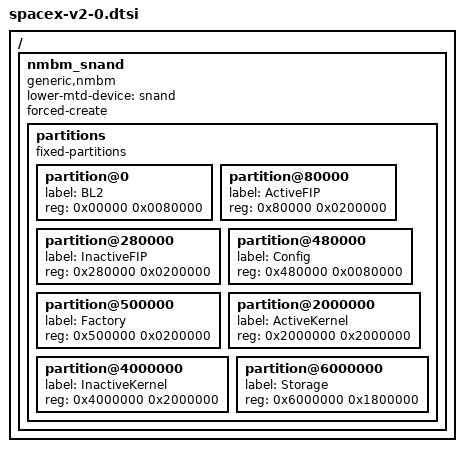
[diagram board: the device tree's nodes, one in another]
/*
 * Copyright (c) 2021 SpaceX.
 * Author: Collin Valley <collin.valley@spacex.com>
 *
 * This program is free software; you can redistribute it and/or modify
 * it under the terms of the GNU General Public License version 2 as
 * published by the Free Software Foundation.
 *
 * This program is distributed in the hope that it will be useful,
 * but WITHOUT ANY WARRANTY; without even the implied warranty of
 * MERCHANTABILITY or FITNESS FOR A PARTICULAR PURPOSE.  See the
 * GNU General Public License for more details.
 */

#include "spacex-v2.dtsi"

/{
	nmbm_snand {
		compatible = "generic,nmbm";

		#address-cells = <1>;
		#size-cells = <1>;

		lower-mtd-device = <&snand>;
		forced-create;

		partitions {
			compatible = "fixed-partitions";
			#address-cells = <1>;
			#size-cells = <1>;

			partition@0 {
				label = "BL2";
				reg = <0x00000 0x0080000>;
			};

			partition@80000 {
				label = "ActiveFIP";
				reg = <0x80000 0x0200000>;
			};

			partition@280000 {
				label = "InactiveFIP";
				reg = <0x280000 0x0200000>;
			};

			partition@480000 {
				label = "Config";
				reg = <0x480000 0x0080000>;
			};

			partition@500000 {
				label = "Factory";
				reg = <0x500000 0x0200000>;
			};

			partition@2000000 {
				label = "ActiveKernel";
				reg = <0x2000000 0x2000000>;
			};

			partition@4000000 {
				label = "InactiveKernel";
				reg = <0x4000000 0x2000000>;
			};

			partition@6000000 {
				label = "Storage";
				reg = <0x6000000 0x1800000>;
			};
		};
	};
};
